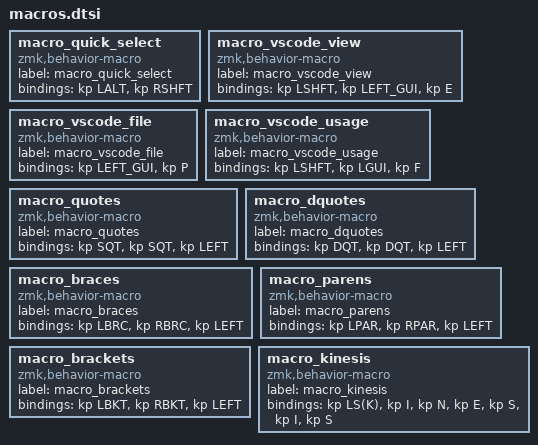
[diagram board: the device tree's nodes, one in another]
macro_quick_select: macro_quick_select{
compatible = "zmk,behavior-macro";
label = "macro_quick_select";
#binding-cells = <0>;
bindings = <&kp LALT>, <&kp RSHFT>;
};
macro_vscode_view: macro_vscode_view{
compatible = "zmk,behavior-macro";
label = "macro_vscode_view";
#binding-cells = <0>;
bindings = <&kp LSHFT>, <&kp LEFT_GUI>, <&kp E>;
};
macro_vscode_file: macro_vscode_file{
compatible = "zmk,behavior-macro";
label = "macro_vscode_file";
#binding-cells = <0>;
bindings = <&kp LEFT_GUI>, <&kp P>;
};
macro_vscode_usage: macro_vscode_usage{
compatible = "zmk,behavior-macro";
label = "macro_vscode_usage";
#binding-cells = <0>;
bindings = <&kp LSHFT>, <&kp LGUI>, <&kp F>;
};
macro_quotes: macro_quotes{
compatible = "zmk,behavior-macro";
label = "macro_quotes";
#binding-cells = <0>;
bindings = <&kp SQT>, <&kp SQT>, <&kp LEFT>;
};
macro_dquotes: macro_dquotes{
compatible = "zmk,behavior-macro";
label = "macro_dquotes";
#binding-cells = <0>;
bindings = <&kp DQT>, <&kp DQT>, <&kp LEFT>;
};
macro_braces: macro_braces{
compatible = "zmk,behavior-macro";
label = "macro_braces";
#binding-cells = <0>;
bindings = <&kp LBRC>, <&kp RBRC>, <&kp LEFT>;
};
macro_parens: macro_parens{
compatible = "zmk,behavior-macro";
label = "macro_parens";
#binding-cells = <0>;
bindings = <&kp LPAR>, <&kp RPAR>, <&kp LEFT>;
};
macro_brackets: macro_brackets{
compatible = "zmk,behavior-macro";
label = "macro_brackets";
#binding-cells = <0>;
bindings = <&kp LBKT>, <&kp RBKT>, <&kp LEFT>;
};
macro_kinesis: macro_kinesis{
compatible = "zmk,behavior-macro";
label = "macro_kinesis";
#binding-cells = <0>;
bindings = <&kp LS(K)>, <&kp I>, <&kp N>, <&kp E>, <&kp S>, <&kp I>, <&kp S>;
};
macro_kinesis: macro_kinesis{
compatible = "zmk,behavior-macro";
label = "macro_kinesis";
#binding-cells = <0>;
bindings = <&kp LS(K)>, <&kp I>, <&kp N>, <&kp E>, <&kp S>, <&kp I>, <&kp S>;
};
